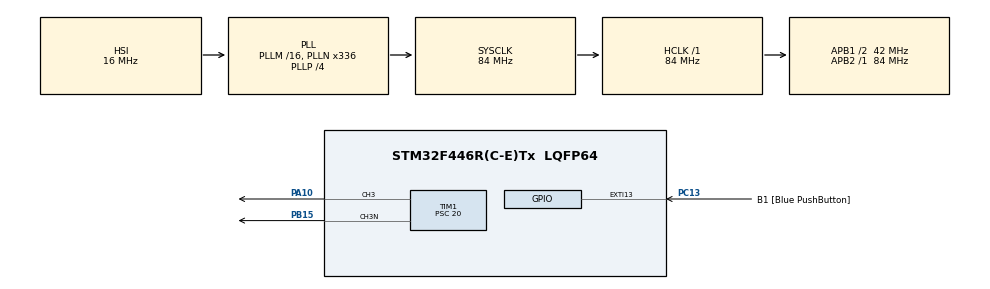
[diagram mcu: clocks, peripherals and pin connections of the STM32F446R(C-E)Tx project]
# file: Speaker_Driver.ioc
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Mcu.Family=STM32F4
Mcu.Name=STM32F446R(C-E)Tx
Mcu.Package=LQFP64
NVIC.PriorityGroup=NVIC_PRIORITYGROUP_0
NVIC.TIM2_IRQn=true\:0\:0\:false\:false\:true
PA10.Signal=S_TIM1_CH3
PA13.GPIO_Label=TMS
PA13.Signal=SYS_JTMS-SWDIO
PA14.GPIO_Label=TCK
PA14.Signal=SYS_JTCK-SWCLK
PA2.GPIO_Label=USART_TX
PA2.Signal=USART2_TX
PA3.GPIO_Label=USART_RX
PA3.Signal=USART2_RX
PB15.Mode=PWM Generation3 CH3 CH3N
PB15.Signal=TIM1_CH3N
PB3.GPIO_Label=SWO
PB3.Signal=SYS_JTDO-SWO
PC13.GPIO_Label=B1 [Blue PushButton]
PC13.GPIO_ModeDefaultEXTI=GPIO_MODE_IT_FALLING
PC13.Signal=GPXTI13
PC14-OSC32_IN.Signal=RCC_OSC32_IN
PC15-OSC32_OUT.Signal=RCC_OSC32_OUT
PH0-OSC_IN.Signal=RCC_OSC_IN
PH1-OSC_OUT.Signal=RCC_OSC_OUT
ProjectManager.HeapSize=0x200
ProjectManager.StackSize=0x400
ProjectManager.TargetToolchain=MDK-ARM V5
RCC.AHBFreq_Value=84000000
RCC.APB1CLKDivider=RCC_HCLK_DIV2
RCC.APB1Freq_Value=42000000
RCC.APB1TimFreq_Value=84000000
RCC.APB2Freq_Value=84000000
RCC.APB2TimFreq_Value=84000000
RCC.CECEnable=false
RCC.ClockTypeHCLK=RCC_CLOCKTYPE_HCLK
RCC.ClockTypePCLK1=RCC_CLOCKTYPE_PCLK1
RCC.ClockTypePCLK2=RCC_CLOCKTYPE_PCLK2
RCC.ClockTypeSysClk=RCC_CLOCKTYPE_SYSCLK
RCC.CortexFreq_Value=84000000
RCC.EnableFMPI2C1=false
RCC.EnableHSE=false
RCC.EnableHSERTCDevisor=false
RCC.EnableI2S1=false
RCC.EnableI2S2=false
RCC.EnableLSE=false
RCC.EnableLSERTC=false
RCC.EnableSAIA=false
RCC.EnableSAIB=false
RCC.EnableSDIO=false
RCC.EnableSPDIF=false
RCC.EnableUSB=false
RCC.EnbaleCSS=false
RCC.ExtClockEnable=false
RCC.FLatency-AdvancedSettings=FLASH_LATENCY_2
RCC.HCLKFreq_Value=84000000
RCC.HSEState=RCC_HSE_OFF
RCC.HSE_VALUE=8000000
RCC.HSIState=RCC_HSI_ON
RCC.HSI_VALUE=16000000
RCC.IWDGEnable=false
RCC.LSE_VALUE=32768
RCC.LSIState=RCC_LSI_OFF
RCC.MCO1OutPutEnable=false
RCC.MCO2OutPutEnable=false
RCC.OscillatorTypeHSI=RCC_OSCILLATORTYPE_HSI
RCC.PLLN=336
RCC.PLLP=RCC_PLLP_DIV4
RCC.PLLSource=RCC_PLLSOURCE_HSI
RCC.PLLState=RCC_PLL_ON
RCC.RCC_RTC_Clock_Source=RCC_RTCCLKSOURCE_LSI
RCC.RTCEnable=false
RCC.SYSCLKFreq_VALUE=84000000
RCC.SYSCLKSource=RCC_SYSCLKSOURCE_PLLCLK
RCC.USBFreq_Value=168000000
RCC.VCOOutputFreq_Value=336000000
SH.S_TIM1_CH3.0=TIM1_CH3,PWM Generation3 CH3 CH3N
TIM1.Channel-PWM\ Generation3\ CH3\ CH3N=TIM_CHANNEL_3
TIM1.Period=100
TIM1.Prescaler=20
TIM1.Pulse-PWM\ Generation3\ CH3\ CH3N=50
TIM2.Period=100
TIM2.Prescaler=41
VP_TIM1_VS_ClockSourceINT.Mode=Internal
VP_TIM2_VS_ClockSourceINT.Mode=Internal
board=NUCLEO-F446RE

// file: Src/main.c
/**
  ******************************************************************************
  * File Name          : main.c
  * Description        : Main program body
  ******************************************************************************
  *
  * COPYRIGHT(c) 2017 STMicroelectronics
  *
  * Redistribution and use in source and binary forms, with or without modification,
  * are permitted provided that the following conditions are met:
  *   1. Redistributions of source code must retain the above copyright notice,
  *      this list of conditions and the following disclaimer.
  *   2. Redistributions in binary form must reproduce the above copyright notice,
  *      this list of conditions and the following disclaimer in the documentation
  *      and/or other materials provided with the distribution.
  *   3. Neither the name of STMicroelectronics nor the names of its contributors
  *      may be used to endorse or promote products derived from this software
  *      without specific prior written permission.
  *
  * THIS SOFTWARE IS PROVIDED BY THE COPYRIGHT HOLDERS AND CONTRIBUTORS "AS IS"
  * AND ANY EXPRESS OR IMPLIED WARRANTIES, INCLUDING, BUT NOT LIMITED TO, THE
  * IMPLIED WARRANTIES OF MERCHANTABILITY AND FITNESS FOR A PARTICULAR PURPOSE ARE
  * DISCLAIMED. IN NO EVENT SHALL THE COPYRIGHT HOLDER OR CONTRIBUTORS BE LIABLE
  * FOR ANY DIRECT, INDIRECT, INCIDENTAL, SPECIAL, EXEMPLARY, OR CONSEQUENTIAL
  * DAMAGES (INCLUDING, BUT NOT LIMITED TO, PROCUREMENT OF SUBSTITUTE GOODS OR
  * SERVICES; LOSS OF USE, DATA, OR PROFITS; OR BUSINESS INTERRUPTION) HOWEVER
  * CAUSED AND ON ANY THEORY OF LIABILITY, WHETHER IN CONTRACT, STRICT LIABILITY,
  * OR TORT (INCLUDING NEGLIGENCE OR OTHERWISE) ARISING IN ANY WAY OUT OF THE USE
  * OF THIS SOFTWARE, EVEN IF ADVISED OF THE POSSIBILITY OF SUCH DAMAGE.
  *
  ******************************************************************************
  */
#include "main.h"
#include "stm32f4xx_hal.h"

TIM_HandleTypeDef htim1;
TIM_HandleTypeDef htim2;

/* USER CODE BEGIN PV */
/* Private variables ---------------------------------------------------------*/

/* USER CODE END PV */

void SystemClock_Config(void);
void Error_Handler(void);
static void MX_GPIO_Init(void);
static void MX_TIM1_Init(void);
static void MX_TIM2_Init(void);
void HAL_TIM_MspPostInit(TIM_HandleTypeDef *htim);

/* USER CODE BEGIN PFP */
/* Private function prototypes -----------------------------------------------*/

/* USER CODE END PFP */

int main(void)
{

  /* MCU Configuration----------------------------------------------------------*/

  /* Reset of all peripherals, Initializes the Flash interface and the Systick. */
  HAL_Init();

  /* Configure the system clock */
  SystemClock_Config();

  /* Initialize all configured peripherals */
  MX_GPIO_Init();
  MX_TIM1_Init();
  MX_TIM2_Init();

  /* USER CODE BEGIN 2 */
	HAL_TIM_Base_Start_IT(&htim2);  //Enable Timer2 interrupt

	// timer1 complementary output start
	HAL_TIM_PWM_Start(&htim1, TIM_CHANNEL_3);
	HAL_TIMEx_PWMN_Start(&htim1, TIM_CHANNEL_3);
	__HAL_TIM_SetCompare(&htim1, TIM_CHANNEL_3, 50);
  /* USER CODE END 2 */

  /* Infinite loop */
  while (1)
  {

  }

}

/** System Clock Configuration
*/
void SystemClock_Config(void)
{

  RCC_OscInitTypeDef RCC_OscInitStruct;
  RCC_ClkInitTypeDef RCC_ClkInitStruct;

    /**Configure the main internal regulator output voltage
    */
  __HAL_RCC_PWR_CLK_ENABLE();

  __HAL_PWR_VOLTAGESCALING_CONFIG(PWR_REGULATOR_VOLTAGE_SCALE3);

    /**Initializes the CPU, AHB and APB busses clocks
    */
  RCC_OscInitStruct.OscillatorType = RCC_OSCILLATORTYPE_HSI;
  RCC_OscInitStruct.HSIState = RCC_HSI_ON;
  RCC_OscInitStruct.HSICalibrationValue = 16;
  RCC_OscInitStruct.PLL.PLLState = RCC_PLL_ON;
  RCC_OscInitStruct.PLL.PLLSource = RCC_PLLSOURCE_HSI;
  RCC_OscInitStruct.PLL.PLLM = 16;
  RCC_OscInitStruct.PLL.PLLN = 336;
  RCC_OscInitStruct.PLL.PLLP = RCC_PLLP_DIV4;
  RCC_OscInitStruct.PLL.PLLQ = 2;
  RCC_OscInitStruct.PLL.PLLR = 2;
  if (HAL_RCC_OscConfig(&RCC_OscInitStruct) != HAL_OK)
  {
    Error_Handler();
  }

    /**Initializes the CPU, AHB and APB busses clocks
    */
  RCC_ClkInitStruct.ClockType = RCC_CLOCKTYPE_HCLK|RCC_CLOCKTYPE_SYSCLK
                              |RCC_CLOCKTYPE_PCLK1|RCC_CLOCKTYPE_PCLK2;
  RCC_ClkInitStruct.SYSCLKSource = RCC_SYSCLKSOURCE_PLLCLK;
  RCC_ClkInitStruct.AHBCLKDivider = RCC_SYSCLK_DIV1;
  RCC_ClkInitStruct.APB1CLKDivider = RCC_HCLK_DIV2;
  RCC_ClkInitStruct.APB2CLKDivider = RCC_HCLK_DIV1;

  if (HAL_RCC_ClockConfig(&RCC_ClkInitStruct, FLASH_LATENCY_2) != HAL_OK)
  {
    Error_Handler();
  }

    /**Configure the Systick interrupt time
    */
  HAL_SYSTICK_Config(HAL_RCC_GetHCLKFreq()/1000);

    /**Configure the Systick
    */
  HAL_SYSTICK_CLKSourceConfig(SYSTICK_CLKSOURCE_HCLK);

  /* SysTick_IRQn interrupt configuration */
  HAL_NVIC_SetPriority(SysTick_IRQn, 0, 0);
}

/* TIM1 init function */
static void MX_TIM1_Init(void)
{

  TIM_ClockConfigTypeDef sClockSourceConfig;
  TIM_MasterConfigTypeDef sMasterConfig;
  TIM_OC_InitTypeDef sConfigOC;
  TIM_BreakDeadTimeConfigTypeDef sBreakDeadTimeConfig;

  htim1.Instance = TIM1;
  htim1.Init.Prescaler = 20;
  htim1.Init.CounterMode = TIM_COUNTERMODE_UP;
  htim1.Init.Period = 100;
  htim1.Init.ClockDivision = TIM_CLOCKDIVISION_DIV1;
  htim1.Init.RepetitionCounter = 0;
  if (HAL_TIM_Base_Init(&htim1) != HAL_OK)
  {
    Error_Handler();
  }

  sClockSourceConfig.ClockSource = TIM_CLOCKSOURCE_INTERNAL;
  if (HAL_TIM_ConfigClockSource(&htim1, &sClockSourceConfig) != HAL_OK)
  {
    Error_Handler();
  }

  if (HAL_TIM_PWM_Init(&htim1) != HAL_OK)
  {
    Error_Handler();
  }

  sMasterConfig.MasterOutputTrigger = TIM_TRGO_RESET;
  sMasterConfig.MasterSlaveMode = TIM_MASTERSLAVEMODE_DISABLE;
  if (HAL_TIMEx_MasterConfigSynchronization(&htim1, &sMasterConfig) != HAL_OK)
  {
    Error_Handler();
  }

  sConfigOC.OCMode = TIM_OCMODE_PWM1;
  sConfigOC.Pulse = 50;
  sConfigOC.OCPolarity = TIM_OCPOLARITY_HIGH;
  sConfigOC.OCNPolarity = TIM_OCNPOLARITY_HIGH;
  sConfigOC.OCFastMode = TIM_OCFAST_DISABLE;
  sConfigOC.OCIdleState = TIM_OCIDLESTATE_RESET;
  sConfigOC.OCNIdleState = TIM_OCNIDLESTATE_RESET;
  if (HAL_TIM_PWM_ConfigChannel(&htim1, &sConfigOC, TIM_CHANNEL_3) != HAL_OK)
  {
    Error_Handler();
  }

  sBreakDeadTimeConfig.OffStateRunMode = TIM_OSSR_DISABLE;
  sBreakDeadTimeConfig.OffStateIDLEMode = TIM_OSSI_DISABLE;
  sBreakDeadTimeConfig.LockLevel = TIM_LOCKLEVEL_OFF;
  sBreakDeadTimeConfig.DeadTime = 0;
  sBreakDeadTimeConfig.BreakState = TIM_BREAK_DISABLE;
  sBreakDeadTimeConfig.BreakPolarity = TIM_BREAKPOLARITY_HIGH;
  sBreakDeadTimeConfig.AutomaticOutput = TIM_AUTOMATICOUTPUT_DISABLE;
  if (HAL_TIMEx_ConfigBreakDeadTime(&htim1, &sBreakDeadTimeConfig) != HAL_OK)
  {
    Error_Handler();
  }

  HAL_TIM_MspPostInit(&htim1);

}

/* TIM2 init function */
static void MX_TIM2_Init(void)
{

  TIM_ClockConfigTypeDef sClockSourceConfig;
  TIM_MasterConfigTypeDef sMasterConfig;

  htim2.Instance = TIM2;
  htim2.Init.Prescaler = 41;
  htim2.Init.CounterMode = TIM_COUNTERMODE_UP;
  htim2.Init.Period = 100;
  htim2.Init.ClockDivision = TIM_CLOCKDIVISION_DIV1;
  if (HAL_TIM_Base_Init(&htim2) != HAL_OK)
  {
    Error_Handler();
  }

  sClockSourceConfig.ClockSource = TIM_CLOCKSOURCE_INTERNAL;
  if (HAL_TIM_ConfigClockSource(&htim2, &sClockSourceConfig) != HAL_OK)
  {
    Error_Handler();
  }

  sMasterConfig.MasterOutputTrigger = TIM_TRGO_RESET;
  sMasterConfig.MasterSlaveMode = TIM_MASTERSLAVEMODE_DISABLE;
  if (HAL_TIMEx_MasterConfigSynchronization(&htim2, &sMasterConfig) != HAL_OK)
  {
    Error_Handler();
  }

}

/** Configure pins as
        * Analog
        * Input
        * Output
        * EVENT_OUT
        * EXTI
     PA2   ------> USART2_TX
     PA3   ------> USART2_RX
*/
static void MX_GPIO_Init(void)
{

  GPIO_InitTypeDef GPIO_InitStruct;

  /* GPIO Ports Clock Enable */
  __HAL_RCC_GPIOC_CLK_ENABLE();
  __HAL_RCC_GPIOH_CLK_ENABLE();
  __HAL_RCC_GPIOA_CLK_ENABLE();
  __HAL_RCC_GPIOB_CLK_ENABLE();

  /*Configure GPIO pin : B1_Pin */
  GPIO_InitStruct.Pin = B1_Pin;
  GPIO_InitStruct.Mode = GPIO_MODE_IT_FALLING;
  GPIO_InitStruct.Pull = GPIO_NOPULL;
  HAL_GPIO_Init(B1_GPIO_Port, &GPIO_InitStruct);

  /*Configure GPIO pins : USART_TX_Pin USART_RX_Pin */
  GPIO_InitStruct.Pin = USART_TX_Pin|USART_RX_Pin;
  GPIO_InitStruct.Mode = GPIO_MODE_AF_PP;
  GPIO_InitStruct.Pull = GPIO_NOPULL;
  GPIO_InitStruct.Speed = GPIO_SPEED_FREQ_VERY_HIGH;
  GPIO_InitStruct.Alternate = GPIO_AF7_USART2;
  HAL_GPIO_Init(GPIOA, &GPIO_InitStruct);

}

void Error_Handler(void)
{
  while(1)
  {
  }
}

/************************ (C) COPYRIGHT STMicroelectronics *****END OF FILE****/
